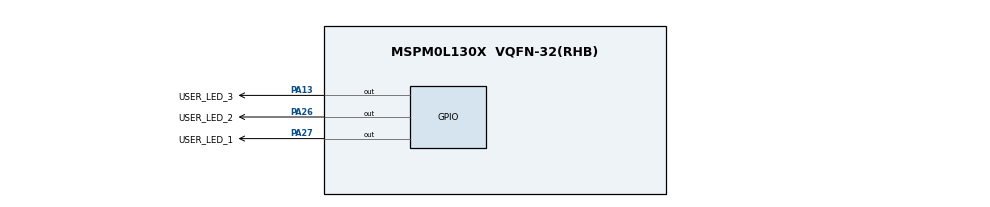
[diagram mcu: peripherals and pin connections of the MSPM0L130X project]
// @cliArgs --device "MSPM0L130X" --package "VQFN-32(RHB)" --part "Default"
// @cliArgs --board /ti/boards/LP_MSPM0L1306 --rtos nortos

/**
 * Import the modules used in this configuration.
 */
const Board  = scripting.addModule("/ti/driverlib/Board");
const GPIO   = scripting.addModule("/ti/driverlib/GPIO", {}, false);
const GPIO1  = GPIO.addInstance();
const SYSCTL = scripting.addModule("/ti/driverlib/SYSCTL");
const TIMER  = scripting.addModule("/ti/driverlib/TIMER", {}, false);
const TIMER1 = TIMER.addInstance();
const TIMER2 = TIMER.addInstance();
const WWDT   = scripting.addModule("/ti/driverlib/WWDT", {}, false);
const WWDT1  = WWDT.addInstance();

/**
 * Write custom configuration values to the imported modules.
 */

GPIO1.$name                                 = "GPIO_LEDS";
GPIO1.associatedPins.create(3);
GPIO1.associatedPins[0].$name               = "USER_LED_1";
GPIO1.associatedPins[0].assignedPin         = "27";
GPIO1.associatedPins[0].assignedPort        = "PORTA";
GPIO1.associatedPins[0].assignedPortSegment = "Upper";
GPIO1.associatedPins[0].pin.$assign         = "PA27";
GPIO1.associatedPins[1].$name               = "USER_LED_2";
GPIO1.associatedPins[1].assignedPin         = "26";
GPIO1.associatedPins[1].assignedPort        = "PORTA";
GPIO1.associatedPins[1].assignedPortSegment = "Upper";
GPIO1.associatedPins[1].pin.$assign         = "PA26";
GPIO1.associatedPins[2].$name               = "USER_LED_3";
GPIO1.associatedPins[2].assignedPort        = "PORTA";
GPIO1.associatedPins[2].assignedPortSegment = "Lower";
GPIO1.associatedPins[2].assignedPin         = "13";
GPIO1.associatedPins[2].pin.$assign         = "PA13";


TIMER1.$name              = "TIMER_0";
TIMER1.timerClkPrescale   = 256;
TIMER1.timerMode          = "PERIODIC";
TIMER1.timerPeriod        = "500 ms";
TIMER1.interrupts         = ["ZERO"];
TIMER1.peripheral.$assign = "TIMG0";

TIMER2.$name              = "TIMER_1";
TIMER2.timerMode          = "PERIODIC";
TIMER2.timerPeriod        = "500 ms";
TIMER2.timerClkPrescale   = 256;
TIMER2.interrupts         = ["ZERO"];
TIMER2.peripheral.$assign = "TIMG1";

WWDT1.$name             = "WWDT0";
WWDT1.wwdtMode          = "INTERVAL";
WWDT1.sleepMode         = true;
WWDT1.enabledInterrupts = true;

SYSCTL.clockTreeEn = true;
